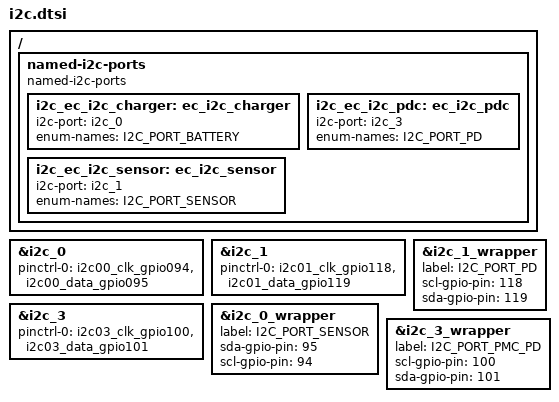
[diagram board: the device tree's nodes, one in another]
/* Copyright 2025 The ChromiumOS Authors
 * Use of this source code is governed by a BSD-style license that can be
 * found in the LICENSE file.
 */

/ {
	named-i2c-ports {
		compatible = "named-i2c-ports";

		i2c_ec_i2c_charger: ec_i2c_charger {
			i2c-port = <&i2c_0>;
			enum-names = "I2C_PORT_BATTERY";
		};
		i2c_ec_i2c_sensor: ec_i2c_sensor {
			i2c-port = <&i2c_1>;
			enum-names = "I2C_PORT_SENSOR";
		};
		i2c_ec_i2c_pdc: ec_i2c_pdc {
			i2c-port = <&i2c_3>;
			enum-names = "I2C_PORT_PD";
		};
	};
};

&i2c_0 {
	pinctrl-0 = <&i2c00_clk_gpio094
		     &i2c00_data_gpio095>;
	pinctrl-names = "default";
	status = "okay";
};

&i2c_1 {
	pinctrl-0 = <&i2c01_clk_gpio118
		     &i2c01_data_gpio119>;
	pinctrl-names = "default";
	status = "okay";
};

&i2c_3 {
	pinctrl-0 = <&i2c03_clk_gpio100
		     &i2c03_data_gpio101>;
	pinctrl-names = "default";
	status = "okay";
};

&i2c_0_wrapper {
	label = "I2C_PORT_SENSOR";
	status = "okay";
	sda-gpio-pin = <95>;
	scl-gpio-pin = <94>;
};
&i2c_1_wrapper {
	label = "I2C_PORT_PD";
	status = "okay";
	scl-gpio-pin = <118>;
	sda-gpio-pin = <119>;
};
&i2c_3_wrapper {
	label = "I2C_PORT_PMC_PD";
	status = "okay";
	scl-gpio-pin = <100>;
	sda-gpio-pin = <101>;
};
